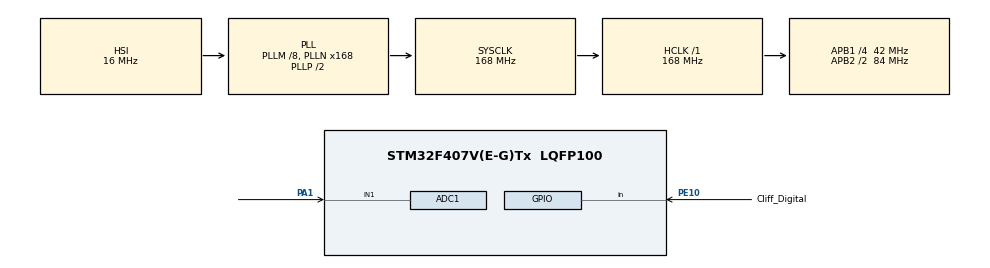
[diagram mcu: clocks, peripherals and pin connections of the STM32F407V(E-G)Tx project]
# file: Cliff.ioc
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ADC1.Channel-2\#ChannelRegularConversion=ADC_CHANNEL_1
ADC1.NbrOfConversionFlag=1
ADC1.Rank-2\#ChannelRegularConversion=1
ADC1.Resolution=ADC_RESOLUTION_10B
ADC1.SamplingTime-2\#ChannelRegularConversion=ADC_SAMPLETIME_3CYCLES
ADC1.master=1
Mcu.Family=STM32F4
Mcu.Name=STM32F407V(E-G)Tx
Mcu.Package=LQFP100
NVIC.PriorityGroup=NVIC_PRIORITYGROUP_0
PA1.Signal=ADCx_IN1
PA13.Mode=Serial_Wire
PA13.Signal=SYS_JTMS-SWDIO
PA14.Mode=Serial_Wire
PA14.Signal=SYS_JTCK-SWCLK
PE10.GPIO_Label=Cliff_Digital
PE10.Signal=GPIO_Input
PH0-OSC_IN.Mode=HSE-External-Oscillator
PH0-OSC_IN.Signal=RCC_OSC_IN
PH1-OSC_OUT.Mode=HSE-External-Oscillator
PH1-OSC_OUT.Signal=RCC_OSC_OUT
ProjectManager.HeapSize=0x200
ProjectManager.StackSize=0x400
ProjectManager.TargetToolchain=STM32CubeIDE
RCC.48MHZClocksFreq_Value=48000000
RCC.AHBFreq_Value=168000000
RCC.APB1CLKDivider=RCC_HCLK_DIV4
RCC.APB1Freq_Value=42000000
RCC.APB1TimFreq_Value=84000000
RCC.APB2CLKDivider=RCC_HCLK_DIV2
RCC.APB2Freq_Value=84000000
RCC.APB2TimFreq_Value=168000000
RCC.CortexFreq_Value=168000000
RCC.HCLKFreq_Value=168000000
RCC.HSE_VALUE=8000000
RCC.HSI_VALUE=16000000
RCC.LSE_VALUE=32768
RCC.PLLM=8
RCC.PLLN=168
RCC.PLLQ=7
RCC.SYSCLKFreq_VALUE=168000000
RCC.SYSCLKSource=RCC_SYSCLKSOURCE_PLLCLK
RCC.VCOOutputFreq_Value=336000000
SH.ADCx_IN1.0=ADC1_IN1,IN1
board=STM32F407G-DISC1

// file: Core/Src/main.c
/* USER CODE BEGIN Header */
/**
  ******************************************************************************
  * @file           : main.c
  * @brief          : Main program body
  ******************************************************************************
  * @attention
  *
  * Copyright (c) 2024 STMicroelectronics.
  * All rights reserved.
  *
  * This software is licensed under terms that can be found in the LICENSE file
  * in the root directory of this software component.
  * If no LICENSE file comes with this software, it is provided AS-IS.
  *
  ******************************************************************************
  */
/* USER CODE END Header */
#include "main.h"
#include "adc.h"
#include "gpio.h"

/* USER CODE BEGIN PTD */
uint8_t D = 0;
uint32_t adcValue = 0;    // Variable to store ADC result
float voltage = 0.0;
float distance = 0.0;
/* USER CODE END PTD */

/* USER CODE BEGIN PD */
float calculate_distance() {
    HAL_ADC_Start(&hadc1);                               // Start ADC
    if (HAL_ADC_PollForConversion(&hadc1, 1000) == HAL_OK) {
        adcValue = HAL_ADC_GetValue(&hadc1);             // Get ADC value (0-4095 for 12-bit ADC)
        voltage = (adcValue / 4095.0) * 3.3;             // Convert ADC value to voltage (0-3.3V)

        // Example sensor distance calculation (Sharp IR sensor GP2Y0A21YK)
        if (voltage > 0.42) {
            distance = 27.86 / (voltage - 0.42);         // Use sensor-specific formula
        } else {
            distance = -1;  // Error condition, voltage too low
        }
    }
    HAL_ADC_Stop(&hadc1);                                // Stop ADC
    return distance;
}
/* USER CODE END PD */

void SystemClock_Config(void);

int main(void)
{

  /* MCU Configuration--------------------------------------------------------*/

  /* Reset of all peripherals, Initializes the Flash interface and the Systick. */
  HAL_Init();

  /* Configure the system clock */
  SystemClock_Config();

  /* Initialize all configured peripherals */
  MX_GPIO_Init();
  MX_ADC1_Init();

  /* Infinite loop */
  /* USER CODE BEGIN WHILE */
  while (1)
  {
//	  D = HAL_GPIO_ReadPin(Cliff_Digital_GPIO_Port, Cliff_Digital_Pin);
//	  HAL_Delay(1000);
//	  HAL_ADC_Start(&hadc1);      // Start ADC conversion
//	          if (HAL_ADC_PollForConversion(&hadc1, 10) == HAL_OK) {
//	              adcValue = HAL_ADC_GetValue(&hadc1);  // Get the converted value
//	              float volt = adcValue * 0.0048828125;
//	              distance =
//
//	          }
//	          HAL_ADC_Stop(&hadc1);       // Stop ADC
	  distance = calculate_distance();
	          HAL_Delay(100);
    /* USER CODE END WHILE */

  }
}

void SystemClock_Config(void)
{
  RCC_OscInitTypeDef RCC_OscInitStruct = {0};
  RCC_ClkInitTypeDef RCC_ClkInitStruct = {0};

  /** Configure the main internal regulator output voltage
  */
  __HAL_RCC_PWR_CLK_ENABLE();
  __HAL_PWR_VOLTAGESCALING_CONFIG(PWR_REGULATOR_VOLTAGE_SCALE1);

  /** Initializes the RCC Oscillators according to the specified parameters
  * in the RCC_OscInitTypeDef structure.
  */
  RCC_OscInitStruct.OscillatorType = RCC_OSCILLATORTYPE_HSI;
  RCC_OscInitStruct.HSIState = RCC_HSI_ON;
  RCC_OscInitStruct.HSICalibrationValue = RCC_HSICALIBRATION_DEFAULT;
  RCC_OscInitStruct.PLL.PLLState = RCC_PLL_ON;
  RCC_OscInitStruct.PLL.PLLSource = RCC_PLLSOURCE_HSI;
  RCC_OscInitStruct.PLL.PLLM = 8;
  RCC_OscInitStruct.PLL.PLLN = 168;
  RCC_OscInitStruct.PLL.PLLP = RCC_PLLP_DIV2;
  RCC_OscInitStruct.PLL.PLLQ = 7;
  if (HAL_RCC_OscConfig(&RCC_OscInitStruct) != HAL_OK)
  {
    Error_Handler();
  }

  /** Initializes the CPU, AHB and APB buses clocks
  */
  RCC_ClkInitStruct.ClockType = RCC_CLOCKTYPE_HCLK|RCC_CLOCKTYPE_SYSCLK
                              |RCC_CLOCKTYPE_PCLK1|RCC_CLOCKTYPE_PCLK2;
  RCC_ClkInitStruct.SYSCLKSource = RCC_SYSCLKSOURCE_PLLCLK;
  RCC_ClkInitStruct.AHBCLKDivider = RCC_SYSCLK_DIV1;
  RCC_ClkInitStruct.APB1CLKDivider = RCC_HCLK_DIV4;
  RCC_ClkInitStruct.APB2CLKDivider = RCC_HCLK_DIV2;

  if (HAL_RCC_ClockConfig(&RCC_ClkInitStruct, FLASH_LATENCY_5) != HAL_OK)
  {
    Error_Handler();
  }
}

void Error_Handler(void)
{
  __disable_irq();
  while (1)
  {
  }
}
